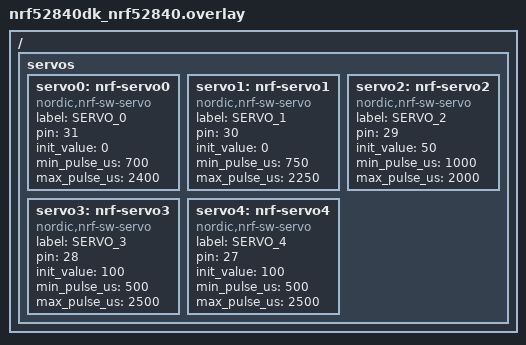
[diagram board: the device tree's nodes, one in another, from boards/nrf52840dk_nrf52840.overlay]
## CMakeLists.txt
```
# SPDX-License-Identifier: Apache-2.0

cmake_minimum_required(VERSION 3.13.1)

find_package(Zephyr REQUIRED HINTS $ENV{ZEPHYR_BASE})
project(servo)

FILE(GLOB app_sources src/*.c)
target_sources(app PRIVATE ${app_sources})
target_include_directories(app PRIVATE include)
```

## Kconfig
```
#
# Copyright (c) 2021 Daniel Veilleux
#
# SPDX-License-Identifier: LicenseRef-BSD-5-Clause-Nordic
#

source "Kconfig.zephyr"

menu "Ultrasonic sensor sample"

choice
	prompt "PWM peripheral"
	default USE_PWM0
	help
		Selects which PWM peripheral to use:
		-  PWM0
		-  PWM1
		-  PWM2
		-  PWM3
	config USE_PWM0
		bool "PWM0"
	  select NRFX_PWM0
	  select NRFX_PWM
	config USE_PWM1
		bool "PWM1"
	  select NRFX_PWM1
 	  select NRFX_PWM
	config USE_PWM2
		bool "PWM2"
	  select NRFX_PWM2
  	  select NRFX_PWM
	config USE_PWM3
		bool "PWM3"
	  select NRFX_PWM3
  	  select NRFX_PWM
endchoice

config PWM_PERIPH_IDX
	int
	default 0 if USE_PWM0
	default 1 if USE_PWM1
	default 2 if USE_PWM2
	default 3 if USE_PWM3

endmenu
```

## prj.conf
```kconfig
# Logging
CONFIG_USE_SEGGER_RTT=y
CONFIG_RTT_CONSOLE=n
CONFIG_UART_CONSOLE=n
CONFIG_CONSOLE=n
CONFIG_STDOUT_CONSOLE=n
CONFIG_PRINTK=n
CONFIG_EARLY_CONSOLE=n

# Drivers and peripherals
CONFIG_I2C=n
CONFIG_WATCHDOG=n
CONFIG_PINMUX=n
CONFIG_SPI=n
CONFIG_SERIAL=n
CONFIG_NFCT_PINS_AS_GPIOS=y

# Power management
CONFIG_SYS_POWER_MANAGEMENT=y

# Interrupts
CONFIG_DYNAMIC_INTERRUPTS=n
CONFIG_IRQ_OFFLOAD=n

# Memory protection
CONFIG_THREAD_CUSTOM_DATA=n
CONFIG_FPU=n

# Boot
CONFIG_BOOT_BANNER=n
CONFIG_BOOT_DELAY=0

# Unneeded features
CONFIG_TIMESLICING=n
CONFIG_MINIMAL_LIBC_MALLOC=n

# Drivers
CONFIG_NRF_SW_SERVO=y
CONFIG_NRF_SW_SERVO_ALLOW_PWM0=n
CONFIG_NRF_SW_SERVO_ALLOW_PWM1=y
CONFIG_NRF_SW_SERVO_ALLOW_PWM2=y
CONFIG_NRF_SW_SERVO_ALLOW_PWM3=n
CONFIG_GPIO=y

# Build
CONFIG_ASSERT=n
CONFIG_SIZE_OPTIMIZATIONS=y
CONFIG_LOG=y
CONFIG_DEBUG=y
```

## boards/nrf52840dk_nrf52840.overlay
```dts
/ {
    servos {
        servo0: nrf-servo0 {
            compatible = "nordic,nrf-sw-servo";
            label = "SERVO_0";
            pin = <31>;
            init_value = <0>;
            min_pulse_us = <700>;
            max_pulse_us = <2400>;
            status = "okay";
        };
		servo1: nrf-servo1 {
            compatible = "nordic,nrf-sw-servo";
            label = "SERVO_1";
            pin = <30>;
            init_value = <0>;
            min_pulse_us = <750>;
            max_pulse_us = <2250>;
            status = "okay";
        };
        servo2: nrf-servo2 {
            compatible = "nordic,nrf-sw-servo";
            label = "SERVO_2";
            pin = <29>;
            init_value = <50>;
            min_pulse_us = <1000>;
            max_pulse_us = <2000>;
            status = "okay";
        };
        servo3: nrf-servo3 {
            compatible = "nordic,nrf-sw-servo";
            label = "SERVO_3";
            pin = <28>;
            init_value = <100>;
            min_pulse_us = <500>;
            max_pulse_us = <2500>;
            status = "okay";
        };
        servo4: nrf-servo4 {
            compatible = "nordic,nrf-sw-servo";
            label = "SERVO_4";
            pin = <27>;
            init_value = <100>;
            min_pulse_us = <500>;
            max_pulse_us = <2500>;
            status = "okay";
        };
    };
};
```

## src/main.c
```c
/*
 * Copyright (c) 2020 Daniel Veilleux
 *
 * SPDX-License-Identifier: Apache-2.0
 */

#include <kernel.h>
#include <string.h>
#include <zephyr.h>
#include <device.h>
#include <stdio.h>
#include <sys/__assert.h>
#include <drivers/servo.h>

#include <logging/log.h>
LOG_MODULE_REGISTER(main, LOG_LEVEL_DBG);

K_TIMER_DEFINE(sync_timer, NULL, NULL);

void main(void)
{
    int ret;
    const struct device *dev;

    if (IS_ENABLED(CONFIG_LOG_BACKEND_RTT)) {
        /* Give RTT log time to be flushed before executing tests */
        k_sleep(K_MSEC(500));
    }

    size_t len = z_device_get_all_static(&dev);
    const struct device *dev_end = dev + len;
    while (dev < dev_end) {
        if (z_device_ready(dev)
            && (dev->name != NULL)
            && (strlen(dev->name) != 0)) {
            LOG_INF("Found device: %s", dev->name);
        }
        dev++;
    }

    dev = device_get_binding("SERVO_0");
    if (dev == NULL) {
        LOG_ERR("Failed to get dev binding");
        return;
    }
    LOG_INF("dev is %p, name is %s", dev, dev->name);

    int step=4;
    k_timer_start(&sync_timer, K_MSEC(0), K_MSEC(500));
    while (1) {
    	int value;

    	step = ((step + 1) % 8);
    	switch(step) {
    	case 0:
    		value = 0;
    		break;
    	case 1:
    		value = 25;
    		break;
    	case 2:
    		value = 50;
    		break;
    	case 3:
    		value = 75;
    		break;
    	case 4:
    		value = 100;
    		break;
        case 5:
            value = 75;
            break;
        case 6:
            value = 50;
            break;
        case 7:
            value = 25;
            break;
        default:
            break;
    	}

    	ret = servo_write(dev, value);
    	if (ret) {
    		LOG_INF("servo_write failed: %d", ret);
    	}
    	k_timer_status_sync(&sync_timer);
    }
    LOG_INF("exiting");
}
```

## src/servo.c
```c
#include "servo.h"

// If this flag is not set in the sequence values that are passed to
// nrf_drv_pwm then the polarity of the PWM waveform will be inverted.
// Inverted values are not useful to a servo so it is assumed that if
// a value in a sequence doesn't have this flag set then that channel
// is not enabled.
#define CH_ENABLED_MASK (0x8000UL)

// The RadioShack micro servo's usable range.
#define RSMS_MIN_VALUE     (600UL)
#define RSMS_MAX_VALUE     (2500UL)
#define RSMS_NEUTRAL_VALUE (((RSMS_MAX_VALUE-RSMS_MIN_VALUE)/2)+RSMS_MIN_VALUE)

// Simple functions for mapping a value betwen [0, 100] to the
// range [RSMS_MIN_VALUE, RSMS_MAX_VALUE] and vice versa.
#define MAP(x) ((x) * (RSMS_MAX_VALUE - RSMS_MIN_VALUE)/100 + RSMS_MIN_VALUE)
#define PAM(x) (((x) - RSMS_MIN_VALUE) * 100 / (RSMS_MAX_VALUE-RSMS_MIN_VALUE))


uint32_t servo_group_init(servo_group_t * p_group,
                              uint8_t ch0_pin,
                              uint8_t ch1_pin,
                              uint8_t ch2_pin,
                              uint8_t ch3_pin)
{
    uint32_t err_code;

    if (NULL == p_group)
    {
        return NRFX_ERROR_INVALID_PARAM;
    }

    p_group->pwm_instance.p_registers  = NRFX_CONCAT_2(NRF_PWM, CONFIG_PWM_PERIPH_IDX);
    p_group->pwm_instance.drv_inst_idx = NRFX_CONCAT_3(NRFX_PWM, CONFIG_PWM_PERIPH_IDX, _INST_IDX);

    nrfx_pwm_config_t const pwm_config =
    {
        .output_pins =
        {
            ch0_pin,
            ch1_pin,
            ch2_pin,
            ch3_pin
        },
        .irq_priority = 0,
        .base_clock   = NRF_PWM_CLK_1MHz,
        .count_mode   = NRF_PWM_MODE_UP,
        .top_value    = 20000, // 20ms
        .load_mode    = NRF_PWM_LOAD_INDIVIDUAL,
        .step_mode    = NRF_PWM_STEP_AUTO
    };

    err_code = nrfx_pwm_init(&p_group->pwm_instance, &pwm_config, NULL, NULL);
    if (NRFX_SUCCESS != err_code)
    {
        return err_code;
    }

    if (SERVO_PIN_NOT_USED != ch0_pin)
    {
        p_group->pwm_values.channel_0 = (CH_ENABLED_MASK|RSMS_NEUTRAL_VALUE);
    }
    else
    {
        p_group->pwm_values.channel_0 = 0;
    }

    if (SERVO_PIN_NOT_USED != ch1_pin)
    {
        p_group->pwm_values.channel_1 = (CH_ENABLED_MASK|RSMS_NEUTRAL_VALUE);
    }
    else
    {
        p_group->pwm_values.channel_1 = 0;
    }

    if (SERVO_PIN_NOT_USED != ch2_pin)
    {
        p_group->pwm_values.channel_2 = (CH_ENABLED_MASK|RSMS_NEUTRAL_VALUE);
    }
    else
    {
        p_group->pwm_values.channel_2 = 0;
    }

    if (SERVO_PIN_NOT_USED != ch3_pin)
    {
        p_group->pwm_values.channel_3 = (CH_ENABLED_MASK|RSMS_NEUTRAL_VALUE);
    }
    else
    {
        p_group->pwm_values.channel_3 = 0;
    }

    nrf_pwm_sequence_t const seq =
    {
        .values.p_individual = &p_group->pwm_values,
        .length              = 4,
        .repeats             = 0,
        .end_delay           = 0
    };
    err_code = nrfx_pwm_simple_playback(&p_group->pwm_instance,
                                            &seq,
                                            1,
                                            NRFX_PWM_FLAG_LOOP);
    /* NOTE: nrfx_pwm_simple_playback returns NULL instead of NRFX_SUCCESS. */
    if (err_code) {
    	return NRFX_ERROR_INTERNAL;
    }
    return NRFX_SUCCESS;
}


uint32_t servo_value_get(servo_group_t * p_group,
                         uint8_t ch_index,
                         uint8_t * p_value)
{
    uint16_t * p_channel_value;

    switch (ch_index)
    {
    case 0:
        p_channel_value = &p_group->pwm_values.channel_0;
        break;
    case 1:
        p_channel_value = &p_group->pwm_values.channel_1;
        break;
    case 2:
        p_channel_value = &p_group->pwm_values.channel_2;
        break;
    case 3:
        p_channel_value = &p_group->pwm_values.channel_3;
        break;
    default:
        return NRFX_ERROR_INVALID_PARAM;
    }

    if (0 == (*p_channel_value & CH_ENABLED_MASK))
    {
        return NRFX_ERROR_INVALID_PARAM;
    }

    *p_value = (uint8_t)PAM((*p_channel_value & ~CH_ENABLED_MASK));

    return NRFX_SUCCESS;
}


uint32_t servo_value_set(servo_group_t * p_group,
                         uint8_t ch_index,
                         uint8_t value)
{
    uint16_t * p_channel_value;

    if (SERVO_MAX_VALUE < value)
    {
        return NRFX_ERROR_INVALID_PARAM;
    }

    switch (ch_index)
    {
    case 0:
        p_channel_value = &p_group->pwm_values.channel_0;
        break;
    case 1:
        p_channel_value = &p_group->pwm_values.channel_1;
        break;
    case 2:
        p_channel_value = &p_group->pwm_values.channel_2;
        break;
    case 3:
        p_channel_value = &p_group->pwm_values.channel_3;
        break;
    default:
        return NRFX_ERROR_INVALID_PARAM;
    }

    if (0 == (*p_channel_value & CH_ENABLED_MASK))
    {
        return NRFX_ERROR_INVALID_PARAM;
    }

    *p_channel_value = (MAP(value) | CH_ENABLED_MASK);

    return NRFX_SUCCESS;
}
```

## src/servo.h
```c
/**
 * A simple wrapper around the nrf_drv_pwm driver's nrf_drv_pwm_simple_playback
 * functionality.
 */
#ifndef SERVO_H
#define SERVO_H

#include "nrfx_pwm.h"

#define SERVO_MIN_VALUE      (0UL)
#define SERVO_NEUTRAL_VALUE  (50UL)
#define SERVO_MAX_VALUE      (100UL)

#define SERVO_PIN_NOT_USED  (NRFX_PWM_PIN_NOT_USED)


// Structs of this type need to kept in the global portion (static) of RAM
// (not const) because they are accessed by EasyDMA.
typedef struct
{
    nrfx_pwm_t pwm_instance;
    nrf_pwm_values_individual_t pwm_values;
} servo_group_t;


// The chX_pins can be set to any GPIO or set to SERVO_PIN_NOT_USED if the channel
// is not required.
uint32_t servo_group_init(servo_group_t * p_group,
                              uint8_t ch0_pin,
                              uint8_t ch1_pin,
                              uint8_t ch2_pin,
                              uint8_t ch3_pin);


// Returns NRFX_ERROR_INVALID_PARAM if the given ch_index is not assigned to a
// pin. The p_value variable will be scaled to the range
// [SERVO_MIN_VALUE, SERVO_MAX_VALUE].
uint32_t servo_value_get(servo_group_t * p_group,
                             uint8_t ch_index,
                             uint8_t * p_value);


// Returns NRFX_ERROR_INVALID_PARAM if the given ch_index is not assigned to a
// pin. The value variable shouldbe be in the range
// [SERVO_MIN_VALUE, SERVO_MAX_VALUE].
uint32_t servo_value_set(servo_group_t * p_group,
                             uint8_t ch_index,
                             uint8_t value);

#endif
```
